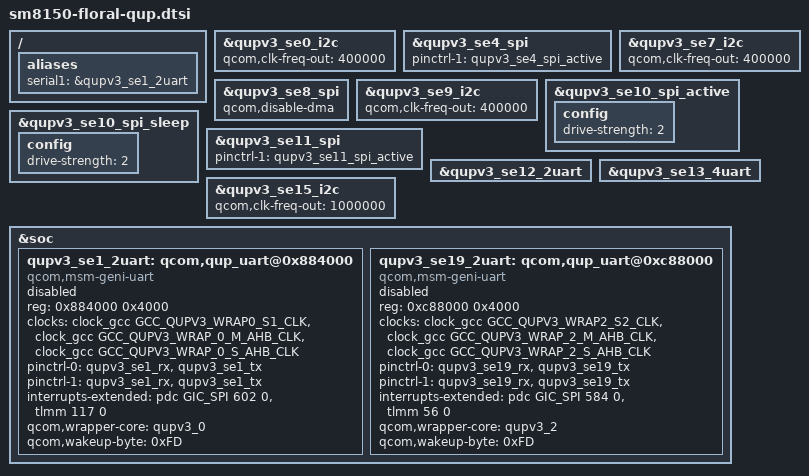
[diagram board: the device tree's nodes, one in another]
/* Copyright (c) 2018, The Linux Foundation. All rights reserved.
 *
 * This program is free software; you can redistribute it and/or modify
 * it under the terms of the GNU General Public License version 2 and
 * only version 2 as published by the Free Software Foundation.
 *
 * This program is distributed in the hope that it will be useful,
 * but WITHOUT ANY WARRANTY; without even the implied warranty of
 * MERCHANTABILITY or FITNESS FOR A PARTICULAR PURPOSE.  See the
 * GNU General Public License for more details.
 */
#include <dt-bindings/clock/qcom,gcc-sm8150.h>
#include <dt-bindings/interrupt-controller/arm-gic.h>

/* p9221, and battery on pre-EVT1.1 */
&qupv3_se0_i2c {
	status = "ok";
	qcom,clk-freq-out = <400000>;
};

/* Touch wants se4 pins active even in suspend. */
&qupv3_se4_spi {
	pinctrl-1 = <&qupv3_se4_spi_active>;
};


/* battery i2c */
&qupv3_se7_i2c {
	status = "ok";
	qcom,clk-freq-out = <400000>;
};

/* ese spi */
&qupv3_se8_spi {
	status = "ok";
	qcom,disable-dma;
};

/* flame/coral pac193x i2c */
&qupv3_se9_i2c {
	qcom,clk-freq-out = <400000>;
};

&qupv3_se10_spi_active {
	config {
		drive-strength = <2>;
	};
};

&qupv3_se10_spi_sleep {
	config {
		drive-strength = <2>;
	};
};

/* Audio wants se11 pins active even in suspend. */
&qupv3_se11_spi {
	pinctrl-1 = <&qupv3_se11_spi_active>;
};

&qupv3_se12_2uart {
	status = "ok";
};

&qupv3_se13_4uart {
	status = "ok";
};

/* Haptics/batt i2c */
&qupv3_se15_i2c {
	qcom,clk-freq-out = <1000000>;
};

&soc {
	/* 2-wire UART on SE1*/
	qupv3_se1_2uart: qcom,qup_uart@0x884000 {
		compatible = "qcom,msm-geni-uart", "qcom,msm-geni-console";
		reg = <0x884000 0x4000>;
		reg-names = "se_phys";
		clock-names = "se-clk", "m-ahb", "s-ahb";
		clocks = <&clock_gcc GCC_QUPV3_WRAP0_S1_CLK>,
		<&clock_gcc GCC_QUPV3_WRAP_0_M_AHB_CLK>,
		<&clock_gcc GCC_QUPV3_WRAP_0_S_AHB_CLK>;
		pinctrl-names = "default", "sleep";
		pinctrl-0 = <&qupv3_se1_rx>, <&qupv3_se1_tx>;
		pinctrl-1 = <&qupv3_se1_rx>, <&qupv3_se1_tx>;
		interrupts-extended = <&pdc GIC_SPI 602 0>, <&tlmm 117 0>;
		qcom,wrapper-core = <&qupv3_0>;
		qcom,wakeup-byte = <0xFD>;
		status = "disabled";
	};

	/* 2-wire UART SE19*/
	qupv3_se19_2uart: qcom,qup_uart@0xc88000 {
		compatible = "qcom,msm-geni-uart", "qcom,msm-geni-console";
		reg = <0xc88000 0x4000>;
		reg-names = "se_phys";
		clock-names = "se-clk", "m-ahb", "s-ahb";
		clocks = <&clock_gcc GCC_QUPV3_WRAP2_S2_CLK>,
		<&clock_gcc GCC_QUPV3_WRAP_2_M_AHB_CLK>,
		<&clock_gcc GCC_QUPV3_WRAP_2_S_AHB_CLK>;
		pinctrl-names = "default", "sleep";
		pinctrl-0 = <&qupv3_se19_rx>, <&qupv3_se19_tx>;
		pinctrl-1 = <&qupv3_se19_rx>, <&qupv3_se19_tx>;
		interrupts-extended = <&pdc GIC_SPI 584 0>, <&tlmm 56 0>;
		qcom,wrapper-core = <&qupv3_2>;
		qcom,wakeup-byte = <0xFD>;
		status = "disabled";
	};
};

/ {
	aliases {
		/* This alias is expected by msm_geni_serial. */
		serial1 = &qupv3_se1_2uart;
	};
};

/*
 * qupv3_se1_2uart is for Airbrush uart on coral/flame.
 * Enabling this can cause backdrive issue on Airbrush prior to EVT1.1.
 */
&qupv3_se1_2uart {
	status = "disabled";
};
